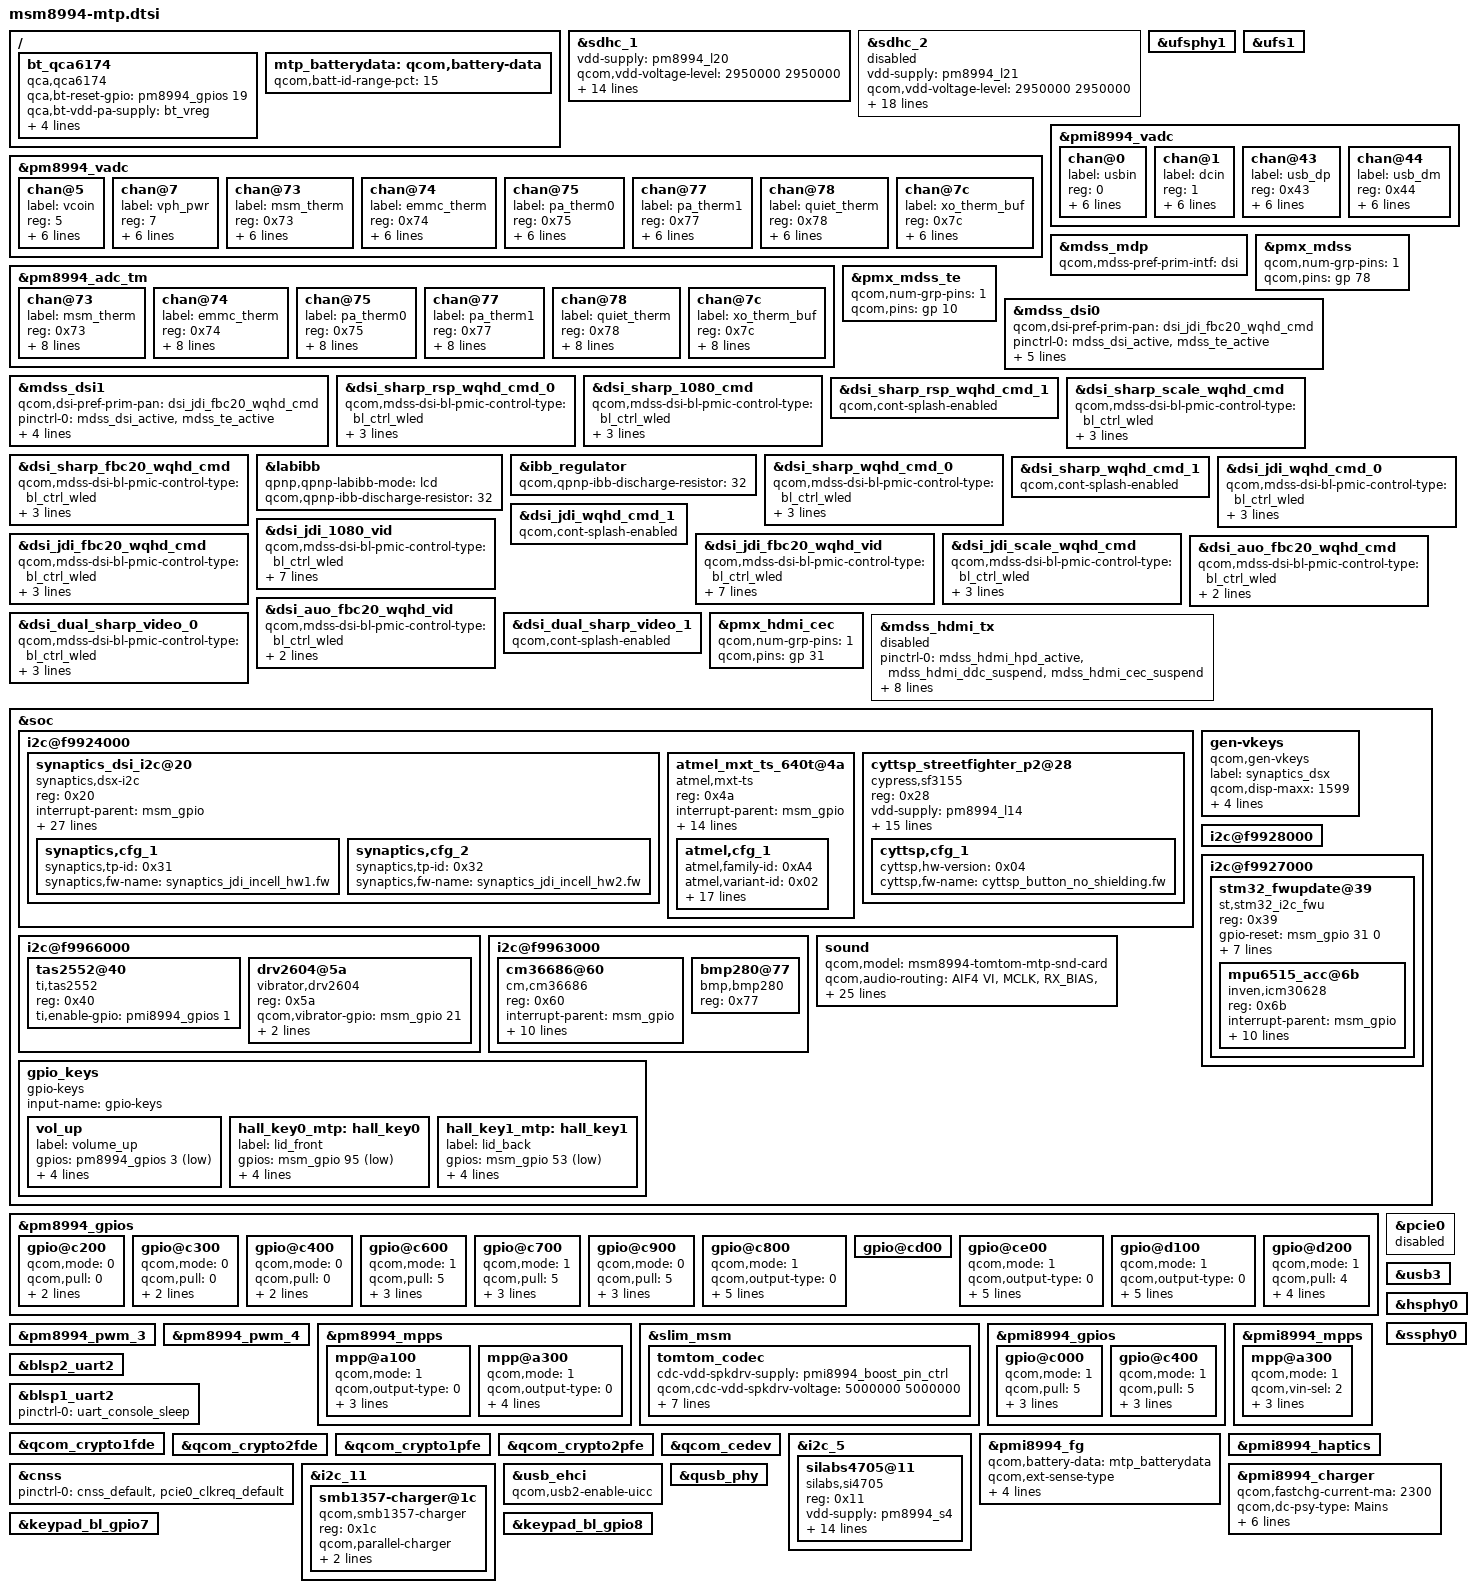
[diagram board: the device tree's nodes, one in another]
/* Copyright (c) 2014-2015, The Linux Foundation. All rights reserved.
 * Copyright (C) 2016 XiaoMi, Inc.
 *
 * This program is free software; you can redistribute it and/or modify
 * it under the terms of the GNU General Public License version 2 and
 * only version 2 as published by the Free Software Foundation.
 *
 * This program is distributed in the hope that it will be useful,
 * but WITHOUT ANY WARRANTY; without even the implied warranty of
 * MERCHANTABILITY or FITNESS FOR A PARTICULAR PURPOSE.  See the
 * GNU General Public License for more details.
 */

#include "msm8994-pinctrl.dtsi"
#include "msm8994-camera-sensor-mtp.dtsi"

/ {
	bt_qca6174 {
		compatible = "qca,qca6174";
		qca,bt-reset-gpio = <&pm8994_gpios 19 0>; /* BT_EN */
		qca,bt-vdd-pa-supply = <&bt_vreg>;
		qca,bt-vdd-io-supply = <&pm8994_s4>;
		qca,bt-vdd-xtal-supply = <&pm8994_l30>;
		qca,bt-vdd-io-voltage-level = <1800000 1800000>;
		qca,bt-vdd-xtal-voltage-level = <1800000 1800000>;
	};
};

&sdhc_1 {
	vdd-supply = <&pm8994_l20>;
	qcom,vdd-voltage-level = <2950000 2950000>;
	qcom,vdd-current-level = <200 570000>;

	vdd-io-supply = <&pm8994_s4>;
	qcom,vdd-io-always-on;
	qcom,vdd-io-voltage-level = <1800000 1800000>;
	qcom,vdd-io-current-level = <200 325000>;

	pinctrl-names = "active", "sleep";
	pinctrl-0 = <&sdc1_clk_on &sdc1_cmd_on &sdc1_data_on &sdc1_rclk_on>;
	pinctrl-1 = <&sdc1_clk_off &sdc1_cmd_off &sdc1_data_off &sdc1_rclk_off>;

	qcom,nonremovable;

	qcom,clk-rates = <400000 20000000 25000000 50000000 100000000 192000000 384000000>;
	qcom,bus-speed-mode = "HS400_1p8v", "HS200_1p8v", "DDR_1p8v";
	status = "ok";
};

&sdhc_2 {
	vdd-supply = <&pm8994_l21>;
	qcom,vdd-voltage-level = <2950000 2950000>;
	qcom,vdd-current-level = <200 800000>;

	vdd-io-supply = <&pm8994_l13>;
	qcom,vdd-io-voltage-level = <1800000 2950000>;
	qcom,vdd-io-current-level = <200 22000>;

	#address-cells = <0>;
	interrupt-parent = <&sdhc_2>;
	interrupts = <0 1 2>;
	#interrupt-cells = <1>;
	interrupt-map-mask = <0xffffffff>;
	interrupt-map = <0 &intc 0 125 0
			1 &intc 0 221 0
			2 &pm8994_gpios 8 0x3>;
	interrupt-names = "hc_irq", "pwr_irq", "status_irq";
	cd-gpios = <&pm8994_gpios 8 0x1>;

	pinctrl-names = "active", "sleep";
	pinctrl-0 = <&sdc2_clk_on &sdc2_cmd_on &sdc2_data_on>;
	pinctrl-1 = <&sdc2_clk_off &sdc2_cmd_off &sdc2_data_off>;

	qcom,clk-rates = <400000 20000000 25000000 50000000 100000000 200000000>;
	qcom,bus-speed-mode = "SDR12", "SDR25", "SDR50", "DDR50", "SDR104";
	status = "disabled";
};

&ufsphy1 {
	status = "ok";
};

&ufs1 {
	status = "ok";
};

&pm8994_vadc {
	chan@5 {
		label = "vcoin";
		reg = <5>;
		qcom,decimation = <0>;
		qcom,pre-div-channel-scaling = <1>;
		qcom,calibration-type = "absolute";
		qcom,scale-function = <0>;
		qcom,hw-settle-time = <0>;
		qcom,fast-avg-setup = <0>;
	};

	chan@7 {
		label = "vph_pwr";
		reg = <7>;
		qcom,decimation = <0>;
		qcom,pre-div-channel-scaling = <1>;
		qcom,calibration-type = "absolute";
		qcom,scale-function = <0>;
		qcom,hw-settle-time = <0>;
		qcom,fast-avg-setup = <0>;
	};

	chan@73 {
		label = "msm_therm";
		reg = <0x73>;
		qcom,decimation = <0>;
		qcom,pre-div-channel-scaling = <0>;
		qcom,calibration-type = "ratiometric";
		qcom,scale-function = <2>;
		qcom,hw-settle-time = <2>;
		qcom,fast-avg-setup = <0>;
	};

	chan@74 {
		label = "emmc_therm";
		reg = <0x74>;
		qcom,decimation = <0>;
		qcom,pre-div-channel-scaling = <0>;
		qcom,calibration-type = "ratiometric";
		qcom,scale-function = <2>;
		qcom,hw-settle-time = <2>;
		qcom,fast-avg-setup = <0>;
	};

	chan@75 {
		label = "pa_therm0";
		reg = <0x75>;
		qcom,decimation = <0>;
		qcom,pre-div-channel-scaling = <0>;
		qcom,calibration-type = "ratiometric";
		qcom,scale-function = <2>;
		qcom,hw-settle-time = <2>;
		qcom,fast-avg-setup = <0>;
	};

	chan@77 {
		label = "pa_therm1";
		reg = <0x77>;
		qcom,decimation = <0>;
		qcom,pre-div-channel-scaling = <0>;
		qcom,calibration-type = "ratiometric";
		qcom,scale-function = <2>;
		qcom,hw-settle-time = <2>;
		qcom,fast-avg-setup = <0>;
	};

	chan@78 {
		label = "quiet_therm";
		reg = <0x78>;
		qcom,decimation = <0>;
		qcom,pre-div-channel-scaling = <0>;
		qcom,calibration-type = "ratiometric";
		qcom,scale-function = <2>;
		qcom,hw-settle-time = <2>;
		qcom,fast-avg-setup = <0>;
	};

	chan@7c {
		label = "xo_therm_buf";
		reg = <0x7c>;
		qcom,decimation = <0>;
		qcom,pre-div-channel-scaling = <0>;
		qcom,calibration-type = "ratiometric";
		qcom,scale-function = <4>;
		qcom,hw-settle-time = <2>;
		qcom,fast-avg-setup = <0>;
	};
};

&pm8994_adc_tm {
	chan@73 {
		label = "msm_therm";
		reg = <0x73>;
		qcom,decimation = <0>;
		qcom,pre-div-channel-scaling = <0>;
		qcom,calibration-type = "ratiometric";
		qcom,scale-function = <2>;
		qcom,hw-settle-time = <2>;
		qcom,fast-avg-setup = <0>;
		qcom,btm-channel-number = <0x48>;
		qcom,thermal-node;
	};

	chan@74 {
		label = "emmc_therm";
		reg = <0x74>;
		qcom,decimation = <0>;
		qcom,pre-div-channel-scaling = <0>;
		qcom,calibration-type = "ratiometric";
		qcom,scale-function = <2>;
		qcom,hw-settle-time = <2>;
		qcom,fast-avg-setup = <0>;
		qcom,btm-channel-number = <0x68>;
		qcom,thermal-node;
	};

	chan@75 {
		label = "pa_therm0";
		reg = <0x75>;
		qcom,decimation = <0>;
		qcom,pre-div-channel-scaling = <0>;
		qcom,calibration-type = "ratiometric";
		qcom,scale-function = <2>;
		qcom,hw-settle-time = <2>;
		qcom,fast-avg-setup = <0>;
		qcom,btm-channel-number = <0x70>;
		qcom,thermal-node;
	};

	chan@77 {
		label = "pa_therm1";
		reg = <0x77>;
		qcom,decimation = <0>;
		qcom,pre-div-channel-scaling = <0>;
		qcom,calibration-type = "ratiometric";
		qcom,scale-function = <2>;
		qcom,hw-settle-time = <2>;
		qcom,fast-avg-setup = <0>;
		qcom,btm-channel-number = <0x78>;
		qcom,thermal-node;
	};

	chan@78 {
		label = "quiet_therm";
		reg = <0x78>;
		qcom,decimation = <0>;
		qcom,pre-div-channel-scaling = <0>;
		qcom,calibration-type = "ratiometric";
		qcom,scale-function = <2>;
		qcom,hw-settle-time = <2>;
		qcom,fast-avg-setup = <0>;
		qcom,btm-channel-number = <0x80>;
		qcom,thermal-node;
	};
	chan@7c {
		label = "xo_therm_buf";
		reg = <0x7c>;
		qcom,decimation = <0>;
		qcom,pre-div-channel-scaling = <0>;
		qcom,calibration-type = "ratiometric";
		qcom,scale-function = <4>;
		qcom,hw-settle-time = <2>;
		qcom,fast-avg-setup = <0>;
		qcom,btm-channel-number = <0x88>;
		qcom,thermal-node;
	};
};

&pmi8994_vadc {
	chan@0 {
		label = "usbin";
		reg = <0>;
		qcom,decimation = <0>;
		qcom,pre-div-channel-scaling = <4>;
		qcom,calibration-type = "absolute";
		qcom,scale-function = <0>;
		qcom,hw-settle-time = <0>;
		qcom,fast-avg-setup = <0>;
	};

	chan@1 {
		label = "dcin";
		reg = <1>;
		qcom,decimation = <0>;
		qcom,pre-div-channel-scaling = <4>;
		qcom,calibration-type = "absolute";
		qcom,scale-function = <0>;
		qcom,hw-settle-time = <0>;
		qcom,fast-avg-setup = <0>;
	};

	chan@43 {
		label = "usb_dp";
		reg = <0x43>;
		qcom,decimation = <0>;
		qcom,pre-div-channel-scaling = <1>;
		qcom,calibration-type = "absolute";
		qcom,scale-function = <0>;
		qcom,hw-settle-time = <0>;
		qcom,fast-avg-setup = <0>;
	};

	chan@44 {
		label = "usb_dm";
		reg = <0x44>;
		qcom,decimation = <0>;
		qcom,pre-div-channel-scaling = <1>;
		qcom,calibration-type = "absolute";
		qcom,scale-function = <0>;
		qcom,hw-settle-time = <0>;
		qcom,fast-avg-setup = <0>;
	};
};

#include "dsi-panel-sharp-dualmipi0-wqxga-video.dtsi"
#include "dsi-panel-sharp-dualmipi1-wqxga-video.dtsi"
#include "dsi-panel-jdi-1080p-video.dtsi"
#include "dsi-panel-auo-fbc20-wqhd-video.dtsi"
#include "dsi-panel-auo-fbc20-wqhd-cmd.dtsi"
#include "dsi-panel-jdi-fbc20-wqhd-cmd.dtsi"
#include "dsi-panel-jdi-fbc20-wqhd-video.dtsi"
#include "dsi-panel-jdi-scale-wqhd-cmd.dtsi"
#include "dsi-panel-jdi-dualmipi0-wqhd-cmd.dtsi"
#include "dsi-panel-jdi-dualmipi1-wqhd-cmd.dtsi"
#include "dsi-panel-sharp-dualmipi0-wqhd-cmd.dtsi"
#include "dsi-panel-sharp-dualmipi1-wqhd-cmd.dtsi"
#include "dsi-panel-sharp-scale-wqhd-cmd.dtsi"
#include "dsi-panel-sharp-fbc20-wqhd-cmd.dtsi"
#include "dsi-panel-sharp-rsp-dualmipi0-wqhd-cmd.dtsi"
#include "dsi-panel-sharp-rsp-dualmipi1-wqhd-cmd.dtsi"
#include "dsi-panel-jdi-1080p-video.dtsi"
#include "dsi-panel-sharp-1080p-cmd.dtsi"

&mdss_mdp {
	qcom,mdss-pref-prim-intf = "dsi";
};

&pmx_mdss {
	qcom,num-grp-pins = <1>;
	qcom,pins = <&gp 78>;
};

&pmx_mdss_te {
	qcom,num-grp-pins = <1>;
	qcom,pins = <&gp 10>;
};

&mdss_dsi0 {
	qcom,dsi-pref-prim-pan = <&dsi_jdi_fbc20_wqhd_cmd>;
	pinctrl-names = "mdss_default", "mdss_sleep";
	pinctrl-0 = <&mdss_dsi_active &mdss_te_active>;
	pinctrl-1 = <&mdss_dsi_suspend &mdss_te_suspend>;
	qcom,dsi-panel-bias-vreg;
	qcom,platform-reset-gpio = <&msm_gpio 78 0>;
	qcom,platform-bklight-en-gpio = <&pmi8994_gpios 2 0>;
        qcom,platform-enable-gpio = <&pm8994_gpios 14 0>;
};

&mdss_dsi1 {
	qcom,dsi-pref-prim-pan = <&dsi_jdi_fbc20_wqhd_cmd>;
	pinctrl-names = "mdss_default", "mdss_sleep";
	pinctrl-0 = <&mdss_dsi_active &mdss_te_active>;
	pinctrl-1 = <&mdss_dsi_suspend &mdss_te_suspend>;
	qcom,dsi-panel-bias-vreg;
	qcom,platform-reset-gpio = <&msm_gpio 78 0>;
	qcom,platform-enable-gpio = <&pm8994_gpios 14 0>;
};

&dsi_sharp_rsp_wqhd_cmd_0 {
	qcom,mdss-dsi-bl-pmic-control-type = "bl_ctrl_wled";
	qcom,mdss-dsi-bl-min-level = <1>;
	qcom,mdss-dsi-bl-max-level = <4095>;
	qcom,cont-splash-enabled;
};

&dsi_sharp_1080_cmd {
	qcom,mdss-dsi-bl-pmic-control-type = "bl_ctrl_wled";
	qcom,mdss-dsi-bl-min-level = <1>;
	qcom,mdss-dsi-bl-max-level = <4095>;
	qcom,cont-splash-enabled;
};

&dsi_sharp_rsp_wqhd_cmd_1 {
	qcom,cont-splash-enabled;
};

&dsi_sharp_scale_wqhd_cmd {
	qcom,mdss-dsi-bl-pmic-control-type = "bl_ctrl_wled";
	qcom,mdss-dsi-bl-min-level = <1>;
	qcom,mdss-dsi-bl-max-level = <4095>;
	qcom,cont-splash-enabled;
};

&dsi_sharp_fbc20_wqhd_cmd {
	qcom,mdss-dsi-bl-pmic-control-type = "bl_ctrl_wled";
	qcom,mdss-dsi-bl-min-level = <1>;
	qcom,mdss-dsi-bl-max-level = <4095>;
	qcom,cont-splash-enabled;
};

&labibb {
	status = "ok";
	qpnp,qpnp-labibb-mode = "lcd";
};

&ibb_regulator {
	qcom,qpnp-ibb-discharge-resistor = <32>;
};

&dsi_sharp_wqhd_cmd_0 {
	qcom,mdss-dsi-bl-pmic-control-type = "bl_ctrl_wled";
	qcom,mdss-dsi-bl-min-level = <1>;
	qcom,mdss-dsi-bl-max-level = <4095>;
	qcom,cont-splash-enabled;
};

&dsi_sharp_wqhd_cmd_1 {
	qcom,cont-splash-enabled;
};

&dsi_jdi_wqhd_cmd_0 {
	qcom,mdss-dsi-bl-pmic-control-type = "bl_ctrl_wled";
	qcom,mdss-dsi-bl-min-level = <1>;
	qcom,mdss-dsi-bl-max-level = <4095>;
	qcom,cont-splash-enabled;
};

&dsi_jdi_wqhd_cmd_1 {
	qcom,cont-splash-enabled;
};

&dsi_jdi_1080_vid {
	qcom,mdss-dsi-bl-pmic-control-type = "bl_ctrl_wled";
	qcom,mdss-dsi-bl-min-level = <1>;
	qcom,mdss-dsi-bl-max-level = <4095>;
};

&dsi_jdi_fbc20_wqhd_cmd {
	qcom,mdss-dsi-bl-pmic-control-type = "bl_ctrl_wled";
	qcom,mdss-dsi-bl-min-level = <1>;
	qcom,mdss-dsi-bl-max-level = <4095>;
	qcom,cont-splash-enabled;
};

&dsi_jdi_fbc20_wqhd_vid {
	qcom,mdss-dsi-bl-pmic-control-type = "bl_ctrl_wled";
	qcom,mdss-dsi-bl-min-level = <1>;
	qcom,mdss-dsi-bl-max-level = <4095>;
	qcom,cont-splash-enabled;
	qcom,mdss-dsi-pan-enable-dynamic-fps;
	qcom,mdss-dsi-pan-fps-update = "dfps_immediate_porch_mode_vfp";
	qcom,mdss-dsi-min-refresh-rate = <30>;
};

&dsi_jdi_scale_wqhd_cmd {
	qcom,mdss-dsi-bl-pmic-control-type = "bl_ctrl_wled";
	qcom,mdss-dsi-bl-min-level = <1>;
	qcom,mdss-dsi-bl-max-level = <4095>;
	qcom,cont-splash-enabled;
};

&dsi_auo_fbc20_wqhd_cmd {
	qcom,mdss-dsi-bl-pmic-control-type = "bl_ctrl_wled";
	qcom,mdss-dsi-bl-min-level = <1>;
	qcom,mdss-dsi-bl-max-level = <4095>;
};

&dsi_auo_fbc20_wqhd_vid {
	qcom,mdss-dsi-bl-pmic-control-type = "bl_ctrl_wled";
	qcom,mdss-dsi-bl-min-level = <1>;
	qcom,mdss-dsi-bl-max-level = <4095>;
};

&dsi_jdi_1080_vid {
	qcom,mdss-dsi-bl-pmic-control-type = "bl_ctrl_wled";
	qcom,mdss-dsi-bl-min-level = <1>;
	qcom,mdss-dsi-bl-max-level = <4095>;
	qcom,cont-splash-enabled;
	qcom,mdss-dsi-pan-enable-dynamic-fps;
	qcom,mdss-dsi-pan-fps-update = "dfps_immediate_porch_mode_vfp";
	qcom,mdss-dsi-min-refresh-rate = <30>;
};

&labibb {
	status = "ok";
	qpnp,qpnp-labibb-mode = "lcd";
	qcom,qpnp-ibb-discharge-resistor = <32>;
};

&dsi_dual_sharp_video_0 {
	qcom,mdss-dsi-bl-pmic-control-type = "bl_ctrl_wled";
	qcom,mdss-dsi-bl-min-level = <1>;
	qcom,mdss-dsi-bl-max-level = <4095>;
	qcom,cont-splash-enabled;
};

&dsi_dual_sharp_video_1 {
	qcom,cont-splash-enabled;
};

&pmx_hdmi_cec {
	qcom,num-grp-pins = <1>;
	qcom,pins = <&gp 31>;
};

&mdss_hdmi_tx {
	pinctrl-names = "hdmi_hpd_active", "hdmi_ddc_active",
				"hdmi_cec_active", "hdmi_active",
				"hdmi_sleep";
	pinctrl-0 = <&mdss_hdmi_hpd_active &mdss_hdmi_ddc_suspend
						&mdss_hdmi_cec_suspend>;
	pinctrl-1 = <&mdss_hdmi_hpd_active &mdss_hdmi_ddc_active
						&mdss_hdmi_cec_suspend>;
	pinctrl-2 = <&mdss_hdmi_hpd_active &mdss_hdmi_cec_active
						&mdss_hdmi_ddc_suspend>;
	pinctrl-3 = <&mdss_hdmi_hpd_active &mdss_hdmi_ddc_active
						&mdss_hdmi_cec_active>;
	pinctrl-4 = <&mdss_hdmi_hpd_suspend &mdss_hdmi_ddc_suspend
						&mdss_hdmi_cec_suspend>;
	status = "disabled";
};

&soc {
	i2c@f9924000 {
		status = "ok";
		synaptics_dsi_i2c@20 {
			compatible = "synaptics,dsx-i2c";
			reg = <0x20>;
			interrupt-parent = <&msm_gpio>;
			interrupts = <61 0x2008>;
			vdd-supply = <&pm8994_l14>;
			avdd-supply = <&disp_vddts_vreg>;
			synaptics,pwr-reg-name = "vdd";
			synaptics,bus-reg-name = "avdd";
			synaptics,ub-i2c-addr = <0x20>;
			pinctrl-names = "pmx_ts_active", "pmx_ts_suspend";
			pinctrl-0 = <&ts_active>;
			pinctrl-1 = <&ts_suspend>;
			synaptics,cut-off-power;
			synaptics,panel-x = <1440>;
			synaptics,panel-y = <2560>;
			synaptics,max-major = <255>;
			synaptics,max-minor = <255>;
			synaptics,max-finger-num = <10>;
			synaptics,reset-gpio = <&msm_gpio 63 0x00>;
			synaptics,irq-gpio = <&msm_gpio 61 0x2008>;
			synaptics,irq-on-state = <0>;
			synaptics,irq-flags = <0x2008>; /* IRQF_ONESHOT | IRQF_TRIGGER_LOW */
			synaptics,power-delay-ms = <160>;
			synaptics,reset-delay-ms = <100>;
			synaptics,reset-active-ms = <20>;
			synaptics,power-on-state = <1>;
			synaptics,reset-on-state = <0>;
			synaptics,cap-button-codes = <139 102 158>;
			synaptics,product-id-as-lockdown;
			synaptics,tp-id-byte = /bits/ 8 <3>;
			synaptics,config-array-size = <2>;
			synaptics,cfg_1 {
				synaptics,tp-id = /bits/ 8 <0x31>;
				synaptics,fw-name = "synaptics_jdi_incell_hw1.fw";
			};
			synaptics,cfg_2 {
				synaptics,tp-id = /bits/ 8 <0x32>;
				synaptics,fw-name = "synaptics_jdi_incell_hw2.fw";
			};
		};
		atmel_mxt_ts_640t@4a {
			compatible = "atmel,mxt-ts";
			reg = <0x4a>;
			interrupt-parent = <&msm_gpio>;
			interrupts = <61 0x2008>;
			vddio-supply = <&pm8994_l14>;
			vdd-supply = <&disp_vddts_vreg>;
			/* pins used by touchscreen */
			pinctrl-names = "pmx_ts_active", "pmx_ts_suspend";
			pinctrl-0 = <&ts_active>;
			pinctrl-1 = <&ts_suspend>;
			atmel,reset-gpio = <&msm_gpio 63 0x00>;
			atmel,irq-gpio = <&msm_gpio 61 0x2008>;
			atmel,mxt-fw-name = "mxT640T15AA.fw";
			atmel,cut-off-power;
			atmel,config-array-size = <1>;
			atmel,default-config = <1>;
			atmel,default-panel-id = <0x38>;
			atmel,irqflags = <0x2008>;
			atmel,gpio-mask = <0x1C>;
			atmel,cfg_1 {
				atmel,family-id = <0xA4>;
				atmel,variant-id = <0x02>;
				atmel,version = <0x15>;
				atmel,build = <0xAA>;
				atmel,rev-id = <0x32>;
				atmel,mxt-cfg-name = "mxt_640t_config.fw";
				atmel,vendor-id = <0x1C>;
				atmel,panel-id = <0x38>;
				atmel,key-codes = <158 102 139>;
				atmel,selfintthr-stylus = <0>;
				atmel,t71-tchthr-pos = <22>;
				atmel,self-chgtime-min = <0>;
				atmel,self-chgtime-max = <0>;
				atmel,mult-intthr-sensitive = <12>;
				atmel,mult-intthr-not-sensitive = <17>;
				atmel,atchthr-sensitive = <6>;
				atmel,mult-tchthr-sensitive = <0>;
				atmel,mult-tchthr-not-sensitive = <0>;
				atmel,wake-up-self-adcx = <0>;
			};
		};
		cyttsp_streetfighter_p2@28 {
			compatible = "cypress,sf3155";
			reg = <0x28>;
			vdd-supply = <&pm8994_l14>;
			avdd-supply = <&disp_vddts_vreg>;
			interrupt-parent = <&msm_gpio>;
			interrupts = <114 0x2002>;
			cyttsp,cut-off-power;
			cyttsp,irq-gpio = <&msm_gpio 114 0x2002>;
			cyttsp,irqflags = <0x2002>;
			cyttsp,input-name = "cyttsp_button";
			cyttsp,key-num = <3>;
			cyttsp,key-codes = <139 102 158>;
			cyttsp,button-status-reg = <0x4A>;
			cyttsp,bootloader-addr = <0x56>;
			cyttsp,config-array-size = <1>;
			cyttsp,standby-reg = <0x01>;
			pinctrl-names = "pmx_btn_active", "pmx_btn_suspend";
			pinctrl-0 = <&btn_active>;
			pinctrl-1 = <&btn_suspend>;
			cyttsp,cfg_1 {
				cyttsp,hw-version = <0x04>;
				cyttsp,fw-name = "cyttsp_button_no_shielding.fw";
			};
		};
	};

	gen-vkeys {
		compatible = "qcom,gen-vkeys";
		label = "synaptics_dsx";
		qcom,disp-maxx = <1599>;
		qcom,disp-maxy = <2559>;
		qcom,panel-maxx = <1599>;
		qcom,panel-maxy = <2703>;
		qcom,key-codes = <158 139 102 217>;
	};

	i2c@f9966000 { /* BLSP2 QUP4 */
		status = "ok";
		tas2552@40 {
			reg = <0x40>;
			compatible = "ti,tas2552";
			ti,enable-gpio = <&pmi8994_gpios 1 0x00>;
		};
		drv2604@5a {
			compatible = "vibrator,drv2604";
			reg = <0x5a>;
			qcom,vibrator-gpio = <&msm_gpio 21 0x00>;
			pinctrl-names = "vibrator_active","vibrator_suspend";
			pinctrl-0 = <&vibrator_active>;
			pinctrl-1 = <&vibrator_suspend>;
		};
	};

	i2c@f9928000 { /* BLSP1 QUP6 */
		status = "ok";
		/*
		nfc-nci@e {
			compatible = "qcom,nfc-nci";
			reg = <0x0e>;
			qcom,irq-gpio = <&msm_gpio 29 0x00>;
			qcom,dis-gpio = <&msm_gpio 30 0x00>;
			qcom,clk-src = "BBCLK2";
			interrupt-parent = <&msm_gpio>;
			interrupts = <29 0>;
			interrupt-names = "nfc_irq";
			pinctrl-names = "nfc_active","nfc_suspend";
			pinctrl-0 = <&nfc_int_active &nfc_disable_active>;
			pinctrl-1 = <&nfc_int_suspend &nfc_disable_suspend>;
			qcom,clk-gpio = <&pm8994_gpios 10 0>;
			qcom,pwr-req-gpio = <&pm8994_gpios 2 0>;
			clocks = <&clock_rpm clk_bb_clk2_pin>;
			clock-names = "ref_clk";
		};
		*/
	};

	i2c@f9927000 {
               stm32_fwupdate@39 {
                        compatible = "st,stm32_i2c_fwu";
                        reg = <0x39>;
                        #address-cells = <1>;
                        #size-cells = <0>;

                        gpio-reset = <&msm_gpio 31 0>;
                        gpio-boot0 = <&msm_gpio 40 0>;
			vdd-supply = <&pm8994_lvs2>;
			mag-supply = <&pm8994_l18>;
                        firmware-name = "st_mve_shub.bin";
                        rx-frame-max-length = <256>;
                        tx-frame-max-length = <0>;
			pinctrl-names = "default";
                        pinctrl-0 = <&sns_boot_default &sns_reset_default>;

			mpu6515_acc@6b {
				compatible = "inven,icm30628";
				reg = <0x6b>;
				interrupt-parent = <&msm_gpio>;
				interrupts = <1 0x2>;

				inven,vdd_ana-supply = <&pm8994_l18>;

				inven,vcc_i2c-supply = <&pm8994_lvs2>;
				inven,gpio_int1 = <&msm_gpio 1 0x00>;

				inven,wake-gpio = <&msm_gpio 39 0x00>;
				inven,wake-delay-us = <300 400>;

				pinctrl-names = "default";
				pinctrl-0 = <&sns_int_default &sns_wakeup_default>;

				inven,accel-orient = <0  255  0  1  0  0  0  0  1>;
				inven,magn-orient = <0  1  0  255  0  0  0  0  1>;
				inven,gyro-orient = <0  255  0  1  0  0  0  0  1>;
			};
                };

        };

	i2c@f9963000 {
		cm36686@60 {
			compatible = "cm,cm36686";
			reg = <0x60>;

			interrupt-parent = <&msm_gpio>;
			interrupts = <90 0x2008>, <102 0x2008>;

			pinctrl-names = "default";
			pinctrl-0 = <&cm36686_int_default &cm36686_int_default_1>;

			vdd-supply = <&pm8994_l18>;
			prox-int-supply = <&pm8994_s4>;
			i2c-supply = <&pm8994_lvs2>;

			als_trans_ratio = <16>;
			prox_default_offset = <1000>;
			prox_thres_near = <300>;
			prox_thres_far = <200>;
                };
		bmp280@77 {
			compatible = "bmp,bmp280";
			reg = <0x77>;
                };

        };

	gpio_keys {
		compatible = "gpio-keys";
		input-name = "gpio-keys";

		vol_up {
			label = "volume_up";
			gpios = <&pm8994_gpios 3 0x1>;
			linux,input-type = <1>;
			linux,code = <115>;
			gpio-key,wakeup;
			debounce-interval = <15>;
		};

		hall_key0_mtp: hall_key0 {
			label = "lid_front";
			gpios = <&msm_gpio 95 0x01>;
			linux,input-type = <5>;
			linux,code = <0>;
			gpio-key,wakeup;
			debounce-interval = <15>;
		};

		hall_key1_mtp: hall_key1 {
			label = "lid_back";
			gpios = <&msm_gpio 53 0x01>;
			linux,input-type = <5>;
			linux,code = <19>;
			gpio-key,wakeup;
			debounce-interval = <15>;
		};
	};

	sound {
		qcom,model = "msm8994-tomtom-mtp-snd-card";

		qcom,audio-routing =
			"AIF4 VI", "MCLK",
			"RX_BIAS", "MCLK",
			"LDO_H", "MCLK",
			"MADINPUT", "MCLK",
			"ultrasound amp", "LINEOUT1",
			"ultrasound amp", "LINEOUT3",
			"AMIC1", "MIC BIAS1 External",
			"MIC BIAS1 External", "Handset Mic",
			"AMIC2", "MIC BIAS2 External",
			"MIC BIAS2 External", "Headset Mic",
			"AMIC3", "MIC BIAS4 External",
			"MIC BIAS4 External", "Analog Mic3",
			"AMIC4", "MIC BIAS4 External",
			"MIC BIAS4 External", "Analog Mic4",
			"AMIC5", "MIC BIAS3 External",
			"MIC BIAS3 External", "Analog Mic5",
			"AMIC6", "MIC BIAS4 External",
			"MIC BIAS4 External", "Analog Mic6",
			"DMIC1", "MIC BIAS1 External",
			"MIC BIAS1 External", "Digital Mic1",
			"DMIC2", "MIC BIAS1 External",
			"MIC BIAS1 External", "Digital Mic2",
			"DMIC3", "MIC BIAS3 External",
			"MIC BIAS3 External", "Digital Mic3",
			"DMIC4", "MIC BIAS3 External",
			"MIC BIAS3 External", "Digital Mic4",
			"DMIC5", "MIC BIAS4 External",
			"MIC BIAS4 External", "Digital Mic5",
			"DMIC6", "MIC BIAS4 External",
			"MIC BIAS4 External", "Digital Mic6";

		qcom,cdc-micbias2-headset-only;
		qcom,mbhc-audio-jack-type = "4-pole-jack";
		asoc-codec = <&stub_codec>;
		asoc-codec-names = "msm-stub-codec.1";
	};
};

&pm8994_gpios {
	gpio@c200 { /* GPIO 3 */
		qcom,mode = <0>;
		qcom,pull = <0>;
		qcom,vin-sel = <2>;
		qcom,src-sel = <0>;
		status = "okay";
	};

	gpio@c300 { /* GPIO 4 */
		qcom,mode = <0>;
		qcom,pull = <0>;
		qcom,vin-sel = <2>;
		qcom,src-sel = <0>;
		status = "okay";
	};

	gpio@c400 { /* GPIO 5 */
		qcom,mode = <0>;
		qcom,pull = <0>;
		qcom,vin-sel = <2>;
		qcom,src-sel = <0>;
		status = "okay";
	};

        gpio@c600 { /* GPIO 7 BUTTON B BACKLIGHT SWITCH */
		qcom,mode = <1>;		/* DIGITAL OUT */
		qcom,pull = <5>;		/* No Pull */
		qcom,vin-sel = <2>;		/* 1.8 */
		qcom,src-sel = <2>;		/* QPMP_PIN_SEL_FUNC_1 */
		qcom,master-en = <1>;
		status = "okay";
	};

	gpio@c700 { /* GPIO 8 BUTTON A BACKLIGHT SWITCH */
		qcom,mode = <1>;		/* DIGITAL OUT */
		qcom,pull = <5>;		/* No Pull */
		qcom,vin-sel = <2>;		/* 1.8 */
		qcom,src-sel = <2>;		/* QPMP_PIN_SEL_FUNC_1 */
		qcom,master-en = <1>;
		status = "okay";
	};

	gpio@c900 { /* GPIO 10 */
		/* NFC clk request */
		qcom,mode = <0>;                /* QPNP_PIN_MODE_DIG_IN */
		qcom,pull = <5>;                /* QPNP_PIN_PULL_NO */
		qcom,vin-sel = <2>;             /* QPNP_PIN_VIN2 */
		qcom,src-sel = <2>;             /* QPNP_PIN_SEL_FUNC_1 */
		qcom,master-en = <1>;
		status = "okay";
	};

	gpio@c800 { /* GPIO 9 */
		qcom,mode = <1>;		/* Digital output */
		qcom,output-type = <0>;		/* CMOS logic */
		qcom,invert = <1>;		/* Output high */
		qcom,vin-sel = <0>;		/* VPH_PWR */
		qcom,src-sel = <0>;		/* Constant */
		qcom,out-strength = <1>;	/* High drive strength */
		qcom,master-en = <1>;		/* Enable GPIO */
		status = "okay";
	};

	gpio@cd00 { /* GPIO 14 */
		status = "okay";
	};

	gpio@ce00 { /* GPIO 15 */
		qcom,mode = <1>;
		qcom,output-type = <0>;
		qcom,pull = <5>;
		qcom,vin-sel = <2>;
		qcom,out-strength = <1>;
		qcom,src-sel = <2>;
		qcom,master-en = <1>;
		status = "okay";
	};

	gpio@d100 { /* GPIO 18 */
		qcom,mode = <1>;		/* Digital output */
		qcom,output-type = <0>;		/* CMOS logic */
		qcom,invert = <0>;		/* Output low initially */
		qcom,vin-sel = <2>;		/* VIN 2 */
		qcom,src-sel = <3>;		/* Function 2 */
		qcom,out-strength = <2>;	/* Medium */
		qcom,master-en = <1>;		/* Enable GPIO */
		status = "okay";
	};

	gpio@d200 { /* GPIO 19 */
		qcom,mode = <1>;         /* Digital output*/
		qcom,pull = <4>;         /* Pulldown 10uA */
		qcom,vin-sel = <2>;      /* VIN2 */
		qcom,src-sel = <0>;      /* GPIO */
		qcom,invert = <0>;       /* Invert */
		qcom,master-en = <1>;    /* Enable GPIO */
		status = "okay";
	};
};

&pm8994_pwm_3 {
	status = "okay";
};

&pm8994_pwm_4 {
	status = "okay";
};

&pm8994_mpps {
	mpp@a100 { /* MPP 2 */
		qcom,mode = <1>;		/* Digital output */
		qcom,output-type = <0>;		/* CMOS logic */
		qcom,vin-sel = <2>;		/* S4 1.8V */
		qcom,src-sel = <0>;		/* Constant */
		qcom,master-en = <1>;		/* Enable GPIO */
		status = "okay";
	};

	mpp@a300 { /* MPP 4 */
		/* HDMI_5v_vreg regulator enable */
		qcom,mode = <1>;		/* Digital output */
		qcom,output-type = <0>;		/* CMOS logic */
		qcom,vin-sel = <2>;		/* S4 1.8V */
		qcom,src-sel = <0>;		/* Constant */
		qcom,master-en = <1>;		/* Enable GPIO */
		qcom,invert = <0>;
		status = "okay";
	};
};

&slim_msm {
	tomtom_codec {
		/*qcom,cdc-micbias1-ext-cap;
		qcom,cdc-micbias3-ext-cap;
		qcom,cdc-micbias4-ext-cap;*/
		cdc-vdd-spkdrv-supply = <&pmi8994_boost_pin_ctrl>;
		qcom,cdc-vdd-spkdrv-voltage = <5000000 5000000>;
		qcom,cdc-vdd-spkdrv-current = <600000>;

		cdc-vdd-spkdrv-2-supply = <&pmi8994_boost_pin_ctrl>;
		qcom,cdc-vdd-spkdrv-2-voltage = <5000000 5000000>;
		qcom,cdc-vdd-spkdrv-2-current = <600000>;

		qcom,cdc-on-demand-supplies = "cdc-vdd-spkdrv",
					      "cdc-vdd-spkdrv-2";
	};
};

&pmi8994_gpios {
	gpio@c000 {	/* GPIO 1  Ultrasound PA EN */
		qcom,mode = <1>;	/* DIGITAL OUT */
		qcom,pull = <5>;	/* No Pull */
		qcom,vin-sel = <2>;	/* 1.8 */
		qcom,src-sel = <0>;	/* CONSTANT */
		qcom,master-en = <1>;	/* ENABLE GPIO */
		status = "okay";
	};

	gpio@c400 {	/* GPIO 5  OTG SWITCH EN */
		qcom,mode = <1>;	/* DIGITAL OUT */
		qcom,pull = <5>;	/* No Pull */
		qcom,vin-sel = <2>;	/* 1.8 */
		qcom,src-sel = <0>;	/* GPIO */
		qcom,master-en = <1>;	/* ENABLE GPIO */
		status = "okay";
	};
};

&pmi8994_mpps {
	mpp@a300 { /* MPP 4 */
		/* WLED FET */
		qcom,mode = <1>;	/* DIGITAL OUT */
		qcom,vin-sel = <2>;	/* VIN2 */
		qcom,src-sel = <5>;	/* DTEST2 */
		qcom,master-en = <1>;
		qcom,invert = <0>;
		status = "okay";
	};
};

&blsp2_uart2 {
	status = "ok";
};

&blsp1_uart2 {
	status= "ok";
	 pinctrl-names = "default";
	 pinctrl-0 = <&uart_console_sleep>;
};

&pcie0 {
	status = "disabled";
};

&usb3 {
	status = "ok";
};

&hsphy0 {
	status = "ok";
};

&ssphy0 {
	status = "ok";
};

&qcom_crypto1fde {
	status = "okay";
};

&qcom_crypto2fde {
	status = "okay";
};

&qcom_crypto1pfe {
	status = "okay";
};

&qcom_crypto2pfe {
	status = "okay";
};

&qcom_cedev {
	status = "okay";
};

&i2c_5 {
	silabs4705@11 { /* SiLabs FM chip, slave id 0x11*/
		status = "ok";
		compatible = "silabs,si4705";
		reg = <0x11>;
		vdd-supply = <&pm8994_s4>;
		silabs,vdd-supply-voltage = <1800000 1800000>;
		va-supply = <&bt_vreg>;
		silabs,va-supply-voltage = <3300000 3300000>;
		pinctrl-names = "pmx_fm_active","pmx_fm_suspend";
		pinctrl-0 = <&fm_int_active &fm_status_int_active &fm_rst_active>;
		pinctrl-1 = <&fm_int_suspend &fm_status_int_suspend &fm_rst_suspend>;
		silabs,reset-gpio = <&msm_gpio 62 0>;
		silabs,int-gpio = <&msm_gpio 9 0>;
		silabs,status-gpio = <&msm_gpio 11 0>;
		#address-cells = <0>;
		interrupts = <0 1>;
		#interrupt-cells = <1>;
		interrupt-map-mask = <0xffffffff>;
		interrupt-map = <
				  0 &msm_gpio 9 2
				  1 &msm_gpio 11 1
				>;
		interrupt-names = "silabs_fm_int", "silabs_fm_status_int";
	};
};

/{
	mtp_batterydata: qcom,battery-data {
		qcom,batt-id-range-pct = <15>;
		#include "batterydata-bm34-lg-3090mah.dtsi"
		#include "batterydata-bm34-samsung-3090mah.dtsi"
		#include "batterydata-itech-3020mah.dtsi"
	};
};

&pmi8994_fg {
	qcom,battery-data = <&mtp_batterydata>;
	qcom,ext-sense-type;
	qcom,warm-bat-decidegc = <450>;
	qcom,cool-bat-decidegc = <100>;
	qcom,hot-bat-decidegc  = <600>;
	qcom,cold-bat-decidegc = <0>;
};

&pmi8994_haptics {
	status = "okay";
};


&cnss {
	pinctrl-names = "default";
	pinctrl-0 = <&cnss_default &pcie0_clkreq_default>;
};

&i2c_11 {
	smb1357-charger@1c {
		compatible = "qcom,smb1357-charger";
		reg = <0x1c>;
		qcom,parallel-charger;
		qcom,float-voltage-mv = <4400>;
		qcom,recharge-thresh-mv = <100>;
	};
};

&usb_ehci {
	status = "ok";
	qcom,usb2-enable-uicc;
};

&qusb_phy {
	status = "ok";
};

&pmi8994_charger {
	qcom,fastchg-current-ma = <2300>;
	qcom,dc-psy-type = "Mains";
	qcom,dc-psy-ma = <1500>;
	qcom,thermal-mitigation = <1500 1200 1000 0>;
	qcom,parallel-usb-min-current-ma = <1400>;
	qcom,parallel-usb-9v-min-current-ma = <900>;
	qcom,parallel-allowed-lowering-ma = <500>;
	qcom,fastchg-current-comp = <900>;
};

&keypad_bl_gpio7 {
	status = "okay";
};

&keypad_bl_gpio8 {
	status = "okay";
};
